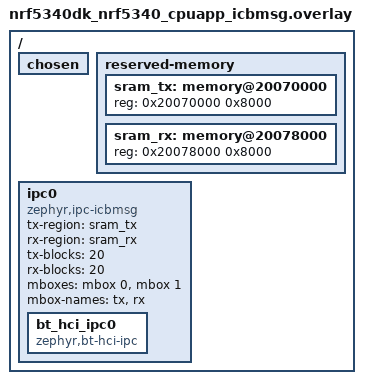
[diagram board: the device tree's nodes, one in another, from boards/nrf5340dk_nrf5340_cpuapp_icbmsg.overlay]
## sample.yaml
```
sample:
  description: Bluetooth Low Energy throughput sample
  name: Bluetooth LE throughput
tests:
  sample.bluetooth.throughput:
    sysbuild: true
    integration_platforms:
      - nrf54l15dk/nrf54l15/cpuapp
    platform_allow:
      - nrf52dk/nrf52832
      - nrf52840dk/nrf52840
      - nrf5340dk/nrf5340/cpuapp
      - nrf5340dk/nrf5340/cpuapp/ns
      - nrf54l15dk/nrf54l05/cpuapp
      - nrf54l15dk/nrf54l10/cpuapp
      - nrf54l15dk/nrf54l15/cpuapp
      - nrf54l15dk/nrf54l15/cpuapp/ns
      - nrf54h20dk/nrf54h20/cpuapp
      - nrf54lm20dk/nrf54lm20a/cpuapp
      - nrf54lm20dk/nrf54lm20a/cpuapp/ns
      - nrf54lm20dk/nrf54lm20b/cpuapp
      - nrf54lm20dk/nrf54lm20b/cpuapp/ns
      - nrf54lv10dk/nrf54lv10a/cpuapp
      - nrf54lv10dk/nrf54lv10a/cpuapp/ns
    tags:
      - bluetooth
      - ci_build
      - sysbuild
      - ci_samples_bluetooth
    harness: console
    harness_config:
      type: multi_line
      ordered: true
      regex:
        - "Starting Bluetooth Throughput sample"
        - "Bluetooth initialized"
    timeout: 15
  sample.bluetooth.throughput.nrf5340dk_nrf5340_cpuapp.icbmsg:
    sysbuild: true
    platform_allow:
      - nrf5340dk/nrf5340/cpuapp
    integration_platforms:
      - nrf5340dk/nrf5340/cpuapp
    extra_args: FILE_SUFFIX=icbmsg
    tags:
      - bluetooth
      - ci_build
      - sysbuild
      - ci_samples_bluetooth
    harness: console
    harness_config:
      type: multi_line
      ordered: true
      regex:
        - "Starting Bluetooth Throughput sample"
        - "Bluetooth initialized"
    timeout: 15
  sample.bluetooth.throughput.nrf5340dk_nrf5340_cpuapp.icmsg:
    sysbuild: true
    platform_allow:
      - nrf5340dk/nrf5340/cpuapp
    integration_platforms:
      - nrf5340dk/nrf5340/cpuapp
    extra_args: FILE_SUFFIX=icmsg
    tags:
      - bluetooth
      - ci_build
      - sysbuild
      - ci_samples_bluetooth
    harness: console
    harness_config:
      type: multi_line
      ordered: true
      regex:
        - "Starting Bluetooth Throughput sample"
        - "Bluetooth initialized"
    timeout: 15
```

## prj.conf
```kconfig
#
# Copyright (c) 2018 Nordic Semiconductor
#
# SPDX-License-Identifier: LicenseRef-Nordic-5-Clause
#
CONFIG_NCS_SAMPLES_DEFAULTS=y

CONFIG_SHELL=y

CONFIG_BT_DEVICE_NAME="Nordic_Throughput"
CONFIG_BT=y
CONFIG_BT_SMP=y
CONFIG_BT_PERIPHERAL=y
CONFIG_BT_CENTRAL=y
CONFIG_BT_MAX_CONN=2
CONFIG_BT_BONDABLE=n

CONFIG_BT_SCAN=y
CONFIG_BT_SCAN_FILTER_ENABLE=y
CONFIG_BT_SCAN_UUID_CNT=1

CONFIG_BT_GATT_CLIENT=y
CONFIG_BT_THROUGHPUT=y

CONFIG_BT_GATT_DM=y
CONFIG_HEAP_MEM_POOL_SIZE=2048

CONFIG_BT_USER_DATA_LEN_UPDATE=y
CONFIG_BT_USER_PHY_UPDATE=y
CONFIG_BT_GAP_AUTO_UPDATE_CONN_PARAMS=n

CONFIG_BT_BUF_ACL_RX_SIZE=502
CONFIG_BT_ATT_PREPARE_COUNT=2
CONFIG_BT_ATT_TX_COUNT=10
CONFIG_BT_L2CAP_TX_MTU=498
CONFIG_BT_L2CAP_DYNAMIC_CHANNEL=y
CONFIG_BT_CONN_TX_MAX=10
CONFIG_BT_BUF_EVT_RX_COUNT=11
CONFIG_BT_BUF_ACL_TX_COUNT=10
CONFIG_BT_BUF_ACL_TX_SIZE=502

CONFIG_BT_CTLR_DATA_LENGTH_MAX=251
CONFIG_BT_CTLR_PHY_2M=y
CONFIG_BT_CTLR_PHY_CODED=y
CONFIG_BT_CTLR_SDC_MAX_CONN_EVENT_LEN_DEFAULT=4000000

CONFIG_DK_LIBRARY=y
CONFIG_DK_LIBRARY_DYNAMIC_BUTTON_HANDLERS=y

CONFIG_BT_FRAME_SPACE_UPDATE=y
CONFIG_BT_LE_EXTENDED_FEAT_SET=y
CONFIG_CPU_LOAD=y
#CONFIG_STATS=y
#CONFIG_STATS_SHELL=y
#CONFIG_IPC_SERVICE_BACKEND_ICBMSG_SHELL=y
CONFIG_PM=y
```

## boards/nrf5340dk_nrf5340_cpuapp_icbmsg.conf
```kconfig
#
# Copyright (c) 2026 Nordic Semiconductor ASA
#
# SPDX-License-Identifier: LicenseRef-Nordic-5-Clause
#

CONFIG_IPC_SERVICE_BACKEND_ICBMSG=y
CONFIG_PBUF_RX_READ_BUF_SIZE=512
```

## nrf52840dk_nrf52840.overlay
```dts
/* SPDX-License-Identifier: Apache-2.0 */

/ {
	chosen {
		/*zephyr,bt-uart=&lpuart;*/
		zephyr,bt-uart=&uart1;
	};
};


&uart1 {
	compatible = "nordic,nrf-uarte";
	current-speed = <1000000>;
	status = "okay";
	rx-pin = <33>;
	tx-pin = <34>;
	rts-pin = <35>;
	cts-pin = <36>;
	hw-flow-control;
};

/*
&uart1 {
	compatible = "nordic,nrf-uarte";
	rx-pin = <33>;
	tx-pin = <34>;
	status = "okay";
	current-speed = <1000000>;
	/delete-property/ rts-pin;
	/delete-property/ cts-pin;

	lpuart: nrf-sw-lpuart {
		compatible = "nordic,nrf-sw-lpuart";
		status = "okay";
		label = "LPUART";
		req-pin = <35>;
		rdy-pin = <36>;
	};
};

*/
```

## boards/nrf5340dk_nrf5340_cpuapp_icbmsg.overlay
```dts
/*
 * Copyright (c) 2026 Nordic Semiconductor ASA
 *
 * SPDX-License-Identifier: LicenseRef-Nordic-5-Clause
 */

/delete-node/ &ipc0;
/delete-node/ &sram0_shared;

/ {
	chosen {
		/delete-property/ zephyr,ipc_shm;
	};

	reserved-memory {
		#address-cells = <1>;
		#size-cells = <1>;
		ranges;

		sram_tx: memory@20070000 {
			reg = <0x20070000 0x8000>;
		};

		sram_rx: memory@20078000 {
			reg = <0x20078000 0x8000>;
		};
	};

	ipc0: ipc0 {
		compatible = "zephyr,ipc-icbmsg";
		tx-region = <&sram_tx>;
		rx-region = <&sram_rx>;
		tx-blocks = <20>;
		rx-blocks = <20>;
		mboxes = <&mbox 0>, <&mbox 1>;
		mbox-names = "tx", "rx";
		status = "okay";

		bt_hci_ipc0: bt_hci_ipc0 {
			compatible = "zephyr,bt-hci-ipc";
			status = "okay";
		};
	};
};
```

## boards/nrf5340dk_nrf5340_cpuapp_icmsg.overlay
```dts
/*
 * Copyright (c) 2026 Nordic Semiconductor ASA
 *
 * SPDX-License-Identifier: LicenseRef-Nordic-5-Clause
 */

/delete-node/ &ipc0;
/delete-node/ &sram0_shared;

/ {
	chosen {
		/delete-property/ zephyr,ipc_shm;
	};

	reserved-memory {
		#address-cells = <1>;
		#size-cells = <1>;
		ranges;

		sram_tx: memory@20070000 {
			reg = <0x20070000 0x8000>;
		};

		sram_rx: memory@20078000 {
			reg = <0x20078000 0x8000>;
		};
	};

	ipc0: ipc0 {
		compatible = "zephyr,ipc-icmsg";
		tx-region = <&sram_tx>;
		rx-region = <&sram_rx>;
		mboxes = <&mbox 0>, <&mbox 1>;
		mbox-names = "tx", "rx";
		unbound = "enable";
		dcache-alignment = <0x20>;
		status = "okay";

		bt_hci_ipc0: bt_hci_ipc0 {
			compatible = "zephyr,bt-hci-ipc";
			status = "okay";
		};
	};
};
```

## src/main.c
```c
/*
 * Copyright (c) 2018 Nordic Semiconductor ASA
 *
 * SPDX-License-Identifier: LicenseRef-Nordic-5-Clause
 */

#include <zephyr/kernel.h>
#include <zephyr/console/console.h>
#include <zephyr/sys/printk.h>
#include <string.h>
#include <stdlib.h>
#include <zephyr/types.h>

#include <zephyr/bluetooth/bluetooth.h>
#include <zephyr/bluetooth/crypto.h>
#include <zephyr/bluetooth/conn.h>
#include <zephyr/bluetooth/gatt.h>
#include <zephyr/bluetooth/hci.h>
#include <zephyr/bluetooth/uuid.h>
#include <bluetooth/services/throughput.h>
#include <bluetooth/scan.h>
#include <bluetooth/gatt_dm.h>
#include <zephyr/debug/cpu_load.h>
#include <zephyr/pm/device.h>
#include <zephyr/pm/device_runtime.h>

#include <zephyr/shell/shell_uart.h>

#include <dk_buttons_and_leds.h>

#include "main.h"

#define DEVICE_NAME	CONFIG_BT_DEVICE_NAME
#define DEVICE_NAME_LEN (sizeof(DEVICE_NAME) - 1)
#define INTERVAL_MIN	0x6	/* 6 units, 7.5 ms, only used to setup connection */
#define INTERVAL_MAX	0x6	/* 6 units, 7.5 ms, only used to setup connection */

#define THROUGHPUT_CONFIG_TIMEOUT K_SECONDS(20)

static K_SEM_DEFINE(throughput_sem, 0, 1);

static volatile bool data_length_req;
static volatile bool test_ready;
static struct bt_conn *default_conn;
static struct bt_throughput throughput;
static const struct bt_uuid *uuid128 = BT_UUID_THROUGHPUT;
static struct bt_gatt_exchange_params exchange_params;
static struct bt_le_conn_param *conn_param =
	BT_LE_CONN_PARAM(INTERVAL_MIN, INTERVAL_MAX, 0, 400);

static const struct bt_data ad[] = {
	BT_DATA_BYTES(BT_DATA_FLAGS, (BT_LE_AD_GENERAL | BT_LE_AD_NO_BREDR)),
	BT_DATA_BYTES(BT_DATA_UUID128_ALL,
		0xBB, 0x4A, 0xFF, 0x4F, 0xAD, 0x03, 0x41, 0x5D,
		0xA9, 0x6C, 0x9D, 0x6C, 0xDD, 0xDA, 0x83, 0x04),
};

static const struct bt_data sd[] = {
	BT_DATA(BT_DATA_NAME_COMPLETE, DEVICE_NAME, DEVICE_NAME_LEN),
};

static void button_handler_cb(uint32_t button_state, uint32_t has_changed);

static const char *phy2str(uint8_t phy)
{
	switch (phy) {
	case 0: return "No packets";
	case BT_GAP_LE_PHY_1M: return "LE 1M";
	case BT_GAP_LE_PHY_2M: return "LE 2M";
	case BT_GAP_LE_PHY_CODED: return "LE Coded";
	default: return "Unknown";
	}
}

static void instruction_print(void)
{
	printk("\nType 'config' to change the configuration parameters.\n");
	printk("You can use the Tab key to autocomplete your input.\n");
	printk("Type 'run' when you are ready to run the test.\n");
}

void scan_filter_match(struct bt_scan_device_info *device_info,
		       struct bt_scan_filter_match *filter_match,
		       bool connectable)
{
	char addr[BT_ADDR_LE_STR_LEN];

	bt_addr_le_to_str(device_info->recv_info->addr, addr, sizeof(addr));

	printk("Filters matched. Address: %s connectable: %d\n",
		addr, connectable);
}

void scan_filter_no_match(struct bt_scan_device_info *device_info,
			  bool connectable)
{
	char addr[BT_ADDR_LE_STR_LEN];

	bt_addr_le_to_str(device_info->recv_info->addr, addr, sizeof(addr));

	printk("Filter not match. Address: %s connectable: %d\n",
				addr, connectable);
}

void scan_connecting_error(struct bt_scan_device_info *device_info)
{
	printk("Connecting failed\n");
}

BT_SCAN_CB_INIT(scan_cb, scan_filter_match, scan_filter_no_match,
		scan_connecting_error, NULL);

static void exchange_func(struct bt_conn *conn, uint8_t att_err,
			  struct bt_gatt_exchange_params *params)
{
	struct bt_conn_info info = {0};
	int err;

	printk("MTU exchange %s\n", att_err == 0 ? "successful" : "failed");

	err = bt_conn_get_info(conn, &info);
	if (err) {
		printk("Failed to get connection info %d\n", err);
		return;
	}

	if (info.role == BT_CONN_ROLE_CENTRAL) {
		instruction_print();
		test_ready = true;
	}
}

static void discovery_complete(struct bt_gatt_dm *dm,
			       void *context)
{
	int err;
	struct bt_throughput *throughput = context;

	printk("Service discovery completed\n");

	bt_gatt_dm_data_print(dm);
	bt_throughput_handles_assign(dm, throughput);
	bt_gatt_dm_data_release(dm);

	exchange_params.func = exchange_func;

	err = bt_gatt_exchange_mtu(default_conn, &exchange_params);
	if (err) {
		printk("MTU exchange failed (err %d)\n", err);
	} else {
		printk("MTU exchange pending\n");
	}
}

static void discovery_service_not_found(struct bt_conn *conn,
					void *context)
{
	printk("Service not found\n");
}

static void discovery_error(struct bt_conn *conn,
			    int err,
			    void *context)
{
	printk("Error while discovering GATT database: (%d)\n", err);
}

struct bt_gatt_dm_cb discovery_cb = {
	.completed         = discovery_complete,
	.service_not_found = discovery_service_not_found,
	.error_found       = discovery_error,
};

static void connected(struct bt_conn *conn, uint8_t hci_err)
{
	struct bt_conn_info info = {0};
	int err;

	if (hci_err) {
		if (hci_err == BT_HCI_ERR_UNKNOWN_CONN_ID) {
			/* Canceled creating connection */
			return;
		}

		printk("Connection failed, err 0x%02x %s\n", hci_err, bt_hci_err_to_str(hci_err));
		return;
	}

	if (default_conn) {
		printk("Connection exists, disconnect second connection\n");
		bt_conn_disconnect(conn, BT_HCI_ERR_REMOTE_USER_TERM_CONN);
		return;
	}

	default_conn = bt_conn_ref(conn);

	err = bt_conn_get_info(default_conn, &info);
	if (err) {
		printk("Failed to get connection info %d\n", err);
		return;
	}

	printk("Connected as %s\n",
	       info.role == BT_CONN_ROLE_CENTRAL ? "central" : "peripheral");
	printk("Conn. interval is %u us\n", info.le.interval_us);

	if (info.role == BT_CONN_ROLE_PERIPHERAL) {
		err = bt_conn_set_security(conn, BT_SECURITY_L2);
		if (err) {
			printk("Failed to set security: %d\n", err);
		}
	}
}

void security_changed(struct bt_conn *conn, bt_security_t level, enum bt_security_err security_err)
{
	printk("Security changed: level %i, err: %i %s\n", level, security_err,
	       bt_security_err_to_str(security_err));

	if (security_err != 0) {
		printk("Failed to encrypt link\n");
		bt_conn_disconnect(conn, BT_HCI_ERR_PAIRING_NOT_SUPPORTED);
		return;
	}

	struct bt_conn_info info = {0};
	int err;

	err = bt_conn_get_info(default_conn, &info);
	if (info.role == BT_CONN_ROLE_CENTRAL) {
		err = bt_gatt_dm_start(default_conn,
				       BT_UUID_THROUGHPUT,
				       &discovery_cb,
				       &throughput);
		if (err) {
			printk("Discover failed (err %d)\n", err);
		}
	}
}

static void scan_init(void)
{
	int err;
	struct bt_le_scan_param scan_param = {
		.type = BT_LE_SCAN_TYPE_PASSIVE,
		.options = BT_LE_SCAN_OPT_FILTER_DUPLICATE,
		.interval = 0x0010,
		.window = 0x0010,
	};

	struct bt_scan_init_param scan_init = {
		.connect_if_match = 1,
		.scan_param = &scan_param,
		.conn_param = conn_param
	};

	bt_scan_init(&scan_init);
	bt_scan_cb_register(&scan_cb);

	err = bt_scan_filter_add(BT_SCAN_FILTER_TYPE_UUID, uuid128);
	if (err) {
		printk("Scanning filters cannot be set\n");

		return;
	}

	err = bt_scan_filter_enable(BT_SCAN_UUID_FILTER, false);
	if (err) {
		printk("Filters cannot be turned on\n");
	}
}

static void scan_start(void)
{
	int err;

	err = bt_scan_start(BT_SCAN_TYPE_SCAN_PASSIVE);
	if (err) {
		printk("Starting scanning failed (err %d)\n", err);
		return;
	}
}

static void adv_start(void)
{
	const struct bt_le_adv_param *adv_param =
		BT_LE_ADV_PARAM(BT_LE_ADV_OPT_CONN,
				BT_GAP_ADV_FAST_INT_MIN_2,
				BT_GAP_ADV_FAST_INT_MAX_2,
				NULL);
	int err;

	err = bt_le_adv_start(adv_param, ad, ARRAY_SIZE(ad), sd,
			      ARRAY_SIZE(sd));
	if (err) {
		printk("Failed to start advertiser (%d)\n", err);
		return;
	}
}

static void disconnected(struct bt_conn *conn, uint8_t reason)
{
	struct bt_conn_info info = {0};
	int err;

	printk("Disconnected, reason 0x%02x %s\n", reason, bt_hci_err_to_str(reason));

	test_ready = false;
	if (default_conn) {
		bt_conn_unref(default_conn);
		default_conn = NULL;
	}

	err = bt_conn_get_info(conn, &info);
	if (err) {
		printk("Failed to get connection info (%d)\n", err);
		return;
	}

	/* Re-connect using same roles */
	if (info.role == BT_CONN_ROLE_CENTRAL) {
		scan_start();
	} else {
		adv_start();
	}
}

static bool le_param_req(struct bt_conn *conn, struct bt_le_conn_param *param)
{
	printk("Connection parameters update request received.\n");
	printk("Minimum interval: %d, Maximum interval: %d\n",
	       param->interval_min, param->interval_max);
	printk("Latency: %d, Timeout: %d\n", param->latency, param->timeout);

	return true;
}

static void le_param_updated(struct bt_conn *conn, uint16_t interval,
			     uint16_t latency, uint16_t timeout)
{
	printk("Connection parameters updated.\n"
	       " interval: %d, latency: %d, timeout: %d\n",
	       interval, latency, timeout);

	k_sem_give(&throughput_sem);
}

static void le_phy_updated(struct bt_conn *conn,
			   struct bt_conn_le_phy_info *param)
{
	printk("LE PHY updated: TX PHY %s, RX PHY %s\n",
	       phy2str(param->tx_phy), phy2str(param->rx_phy));

	k_sem_give(&throughput_sem);
}

static void le_data_length_updated(struct bt_conn *conn,
				   struct bt_conn_le_data_len_info *info)
{
	if (!data_length_req) {
		return;
	}

	printk("LE data len updated: TX (len: %d time: %d)"
	       " RX (len: %d time: %d)\n", info->tx_max_len,
	       info->tx_max_time, info->rx_max_len, info->rx_max_time);

	data_length_req = false;
	k_sem_give(&throughput_sem);
}

#if defined(CONFIG_BT_FRAME_SPACE_UPDATE)
static void frame_space_updated(struct bt_conn *conn,
				const struct bt_conn_le_frame_space_updated *params)
{
	if (params->status != BT_HCI_ERR_SUCCESS) {
		printk("Frame space update failed: %d\n", params->status);
		return;
	}

	printk("Frame space updated: frame space %d us, PHYs 0x%04x, spacing types 0x%04x\n",
	       params->frame_space, params->phys, params->spacing_types);

	k_sem_give(&throughput_sem);
}
#endif

static uint8_t throughput_read(const struct bt_throughput_metrics *met)
{
	printk("[peer] received %u bytes (%u KB)"
	       " in %u GATT writes at %u bps\n",
	       met->write_len, met->write_len / 1024, met->write_count,
	       met->write_rate);

	k_sem_give(&throughput_sem);

	return BT_GATT_ITER_STOP;
}

static void throughput_received(const struct bt_throughput_metrics *met)
{
	static uint32_t kb;

	if (met->write_len == 0) {
		kb = 0;
		printk("\n");

		return;
	}

	if ((met->write_len / 1024) != kb) {
		kb = (met->write_len / 1024);
		printk("=");
	}
}

static void throughput_send(const struct bt_throughput_metrics *met)
{
	int load = cpu_load_get(true);
	printk("CPU load: %d.%d\n", load / 10, load % 10);
	printk("\n[local] received %u bytes (%u KB)"
		" in %u GATT writes at %u bps\n",
		met->write_len, met->write_len / 1024,
		met->write_count, met->write_rate);
}

static const struct bt_throughput_cb throughput_cb = {
	.data_read = throughput_read,
	.data_received = throughput_received,
	.data_send = throughput_send
};

static struct button_handler button = {
	.cb = button_handler_cb,
};

void select_role(bool is_central)
{
	int err;
	static bool role_selected;

	if (role_selected) {
		printk("\nCannot change role after it was selected once.\n");
		return;
	} else if (is_central) {
		printk("\nCentral. Starting scanning\n");
		scan_start();
	} else {
		printk("\nPeripheral. Starting advertising\n");
		adv_start();
	}

	role_selected = true;

	/* The role has been selected, button are not needed any more. */
	err = dk_button_handler_remove(&button);
	if (err) {
		printk("Button disable error: %d\n", err);
	}
}

static void button_handler_cb(uint32_t button_state, uint32_t has_changed)
{
	ARG_UNUSED(has_changed);

	if (button_state & DK_BTN1_MSK) {
		select_role(true);
	} else if (button_state & DK_BTN2_MSK) {
		select_role(false);
	}
}

static void buttons_init(void)
{
	int err;

	err = dk_buttons_init(NULL);
	if (err) {
		printk("Buttons initialization failed.\n");
		return;
	}

	/* Add dynamic buttons handler. Buttons should be activated only when
	 * during the board role choosing.
	 */
	dk_button_handler_add(&button);
}

static int connection_configuration_set(const struct shell *shell,
			const struct bt_le_conn_param *conn_param,
			const struct bt_conn_le_phy_param *phy,
			const struct bt_conn_le_data_len_param *data_len,
			uint16_t frame_space_us)
{
	int err;
	struct bt_conn_info info = {0};

	err = bt_conn_get_info(default_conn, &info);
	if (err) {
		shell_error(shell, "Failed to get connection info %d", err);
		return err;
	}

	if (info.role != BT_CONN_ROLE_CENTRAL) {
		shell_error(shell,
		"'run' command shall be executed only on the central board");
	}

	err = bt_conn_le_phy_update(default_conn, phy);
	if (err) {
		shell_error(shell, "PHY update failed: %d\n", err);
		return err;
	}

	shell_print(shell, "PHY update pending");
	err = k_sem_take(&throughput_sem, THROUGHPUT_CONFIG_TIMEOUT);
	if (err) {
		shell_error(shell, "PHY update timeout");
		return err;
	}

	if (BT_GAP_US_TO_CONN_INTERVAL(info.le.interval_us) != conn_param->interval_max) {
		err = bt_conn_le_param_update(default_conn, conn_param);
		if (err) {
			shell_error(shell,
				    "Connection parameters update failed: %d",
				    err);
			return err;
		}

		shell_print(shell, "Connection parameters update pending");
		err = k_sem_take(&throughput_sem, THROUGHPUT_CONFIG_TIMEOUT);
		if (err) {
			shell_error(shell,
				    "Connection parameters update timeout");
			return err;
		}
	}

	if (info.le.data_len->tx_max_len != data_len->tx_max_len) {
		data_length_req = true;

		err = bt_conn_le_data_len_update(default_conn, data_len);
		if (err) {
			shell_error(shell, "LE data length update failed: %d",
				    err);
			return err;
		}

		shell_print(shell, "LE Data length update pending");
		err = k_sem_take(&throughput_sem, THROUGHPUT_CONFIG_TIMEOUT);
		if (err) {
			shell_error(shell, "LE Data Length update timeout");
			return err;
		}
	}

	if (IS_ENABLED(CONFIG_BT_FRAME_SPACE_UPDATE)) {
		struct bt_conn_le_frame_space_update_param fsu_params;

		fsu_params.frame_space_min = frame_space_us;
		fsu_params.frame_space_max = MAX(150, frame_space_us);
		fsu_params.phys = phy->pref_tx_phy | phy->pref_rx_phy;
		fsu_params.spacing_types = BT_CONN_LE_FRAME_SPACE_TYPES_MASK_ACL_IFS;
		err = bt_conn_le_frame_space_update(default_conn, &fsu_params);
		if (err) {
			shell_error(shell, "Frame space update failed: %d\n", err);
			return err;
		}

		shell_print(shell, "Frame space update pending");
		err = k_sem_take(&throughput_sem, THROUGHPUT_CONFIG_TIMEOUT);
		if (err) {
			shell_error(shell, "Frame space update timeout");
			return err;
		}
	}

	return 0;
}

int stop_shell_uart(const struct shell *sh)
{
	static const struct device *uart = DEVICE_DT_GET(DT_CHOSEN(zephyr_shell_uart));
	int pm_cnt = 0;
	int rv;

	if (IS_ENABLED(CONFIG_PM_DEVICE_RUNTIME)) {
		enum pm_device_state state;

		/* Disable UART to reduce the current consumption. */
		do {
			rv = pm_device_state_get(uart, &state);
			if (rv < 0) {
				return rv;
			}
			if (state != PM_DEVICE_STATE_ACTIVE) {
				break;
			}
			pm_device_runtime_put(uart);
			pm_cnt++;
		} while (1);
	}

	return pm_cnt;
}

void restart_shell_uart(const struct shell *sh, int pm_cnt)
{
	static const struct device *uart = DEVICE_DT_GET(DT_CHOSEN(zephyr_shell_uart));

	if (IS_ENABLED(CONFIG_PM_DEVICE_RUNTIME)) {
		for (int i = 0; i < pm_cnt; i++) {
			pm_device_runtime_get(uart);
		}
	}
}

int test_run(const struct shell *shell,
	     const struct bt_le_conn_param *conn_param,
	     const struct bt_conn_le_phy_param *phy,
	     const struct bt_conn_le_data_len_param *data_len,
	     uint16_t frame_space_us)
{
	int err;
	uint64_t stamp;
	int64_t delta;
	uint32_t data = 0;

	/* a dummy data buffer */
	static char dummy[CONFIG_BT_L2CAP_TX_MTU - 3];

	if (!default_conn) {
		shell_error(shell, "Device is disconnected %s",
			    "Connect to the peer device before running test");
		return -EFAULT;
	}

	if (!test_ready) {
		shell_error(shell, "Device is not ready."
			"Please wait for the service discovery and MTU exchange end");
		return 0;
	}

	shell_print(shell, "\n==== Starting throughput test ====");

	err = connection_configuration_set(shell, conn_param, phy, data_len, frame_space_us);
	if (err) {
		return err;
	}

	shell_print(shell, "The test is in progress and will require around %d seconds "
		"to complete.", CONFIG_BT_THROUGHPUT_DURATION / 1000);

	/* Make sure that all BLE procedures are finished. */
	k_sleep(K_MSEC(500));

	/* reset peer metrics */
	err = bt_throughput_write(&throughput, dummy, 1);
	if (err) {
		shell_error(shell, "Reset peer metrics failed.");
		return err;
	}

	/* get cycle stamp */
	stamp = k_uptime_get_32();
	cpu_load_get(true);

	int pm_cnt = stop_shell_uart(shell);

	while (true) {
		err = bt_throughput_write(&throughput, dummy, sizeof(dummy));
		if (err) {
			shell_error(shell, "GATT write failed (err %d)", err);
			break;
		}
		data += sizeof(dummy);
		if (k_uptime_get_32() - stamp > CONFIG_BT_THROUGHPUT_DURATION) {
			break;
		}
	}

	delta = k_uptime_delta(&stamp);

	int load = cpu_load_get(true);
	restart_shell_uart(shell, pm_cnt);
	printk("\nDone, CPU load: %d.%d\n", load / 10, load % 10);
	printk("[local] sent %u bytes (%u KB) in %lld ms at %llu kbps\n",
	       data, data / 1024, delta, ((uint64_t)data * 8 / delta));

	/* read back char from peer */
	err = bt_throughput_read(&throughput);
	if (err) {
		shell_error(shell, "GATT read failed (err %d)", err);
		return err;
	}

	k_sem_take(&throughput_sem, THROUGHPUT_CONFIG_TIMEOUT);

	instruction_print();

	return 0;
}

BT_CONN_CB_DEFINE(conn_callbacks) = {
	.connected = connected,
	.disconnected = disconnected,
	.le_param_req = le_param_req,
	.le_param_updated = le_param_updated,
	.le_phy_updated = le_phy_updated,
	.le_data_len_updated = le_data_length_updated,
#if defined(CONFIG_BT_FRAME_SPACE_UPDATE)
	.frame_space_updated = frame_space_updated,
#endif
	.security_changed = security_changed
};

int main(void)
{
	int err;

	printk("Starting Bluetooth Throughput sample\n");

	err = bt_enable(NULL);
	if (err) {
		printk("Bluetooth init failed (err %d)\n", err);
		return 0;
	}

	printk("Bluetooth initialized\n");

	scan_init();

	err = bt_throughput_init(&throughput, &throughput_cb);
	if (err) {
		printk("Throughput service initialization failed.\n");
		return 0;
	}

	printk("\n");

	if (IS_ENABLED(CONFIG_SOC_SERIES_NRF54H) || IS_ENABLED(CONFIG_SOC_SERIES_NRF54L)) {
		printk("Press button 0 or type \"central\" on the central board.\n");
		printk("Press button 1 or type \"peripheral\" on the peripheral board.\n");
	} else {
		printk("Press button 1 or type \"central\" on the central board.\n");
		printk("Press button 2 or type \"peripheral\" on the peripheral board.\n");
	}

	buttons_init();

	return 0;
}
```
